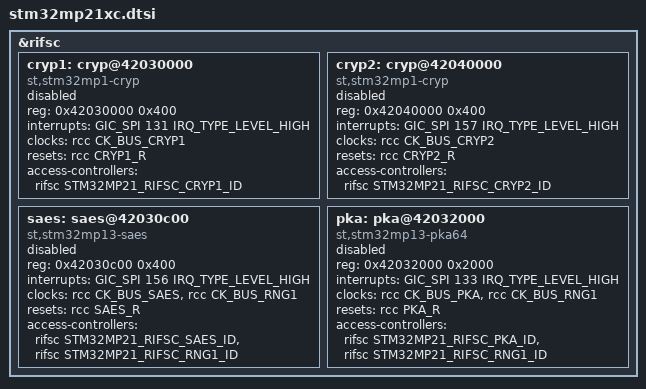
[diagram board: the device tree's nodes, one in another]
// SPDX-License-Identifier: (GPL-2.0-only OR BSD-3-Clause)
/*
 * Copyright (C) 2025, STMicroelectronics - All Rights Reserved
 * Author: Alexandre Torgue <alexandre.torgue@foss.st.com> for STMicroelectronics.
 */

&rifsc {
	cryp1: cryp@42030000 {
		compatible = "st,stm32mp1-cryp";
		reg = <0x42030000 0x400>;
		interrupts = <GIC_SPI 131 IRQ_TYPE_LEVEL_HIGH>;
		clocks = <&rcc CK_BUS_CRYP1>;
		resets = <&rcc CRYP1_R>;
		access-controllers = <&rifsc STM32MP21_RIFSC_CRYP1_ID>;
		status = "disabled";
	};

	cryp2: cryp@42040000 {
		compatible = "st,stm32mp1-cryp";
		reg = <0x42040000 0x400>;
		interrupts = <GIC_SPI 157 IRQ_TYPE_LEVEL_HIGH>;
		clocks = <&rcc CK_BUS_CRYP2>;
		resets = <&rcc CRYP2_R>;
		access-controllers = <&rifsc STM32MP21_RIFSC_CRYP2_ID>;
		status = "disabled";
	};

	saes: saes@42030c00 {
		compatible = "st,stm32mp13-saes";
		reg = <0x42030c00 0x400>;
		interrupts = <GIC_SPI 156 IRQ_TYPE_LEVEL_HIGH>;
		clocks = <&rcc CK_BUS_SAES>, <&rcc CK_BUS_RNG1>;
		clock-names = "bus", "rng";
		resets = <&rcc SAES_R>;
		access-controllers = <&rifsc STM32MP21_RIFSC_SAES_ID>, <&rifsc STM32MP21_RIFSC_RNG1_ID>;
		status = "disabled";
	};

	pka: pka@42032000 {
		compatible = "st,stm32mp13-pka64";
		reg = <0x42032000 0x2000>;
		interrupts = <GIC_SPI 133 IRQ_TYPE_LEVEL_HIGH>;
		clocks = <&rcc CK_BUS_PKA>, <&rcc CK_BUS_RNG1>;
		clock-names = "bus", "rng";
		resets = <&rcc PKA_R>;
		access-controllers = <&rifsc STM32MP21_RIFSC_PKA_ID>, <&rifsc STM32MP21_RIFSC_RNG1_ID>;
		status = "disabled";
	};
};
